# iostm32f105xx register map
Registers are 32-bit, access not given, no defined reset value unless marked. A register's access mark holds for its fields unless they carry their own. Addresses are absolute; registers are grouped by the start of their names; [hi:lo] are bit positions; {n}, {i} and the like mark numbered series.

## OTG
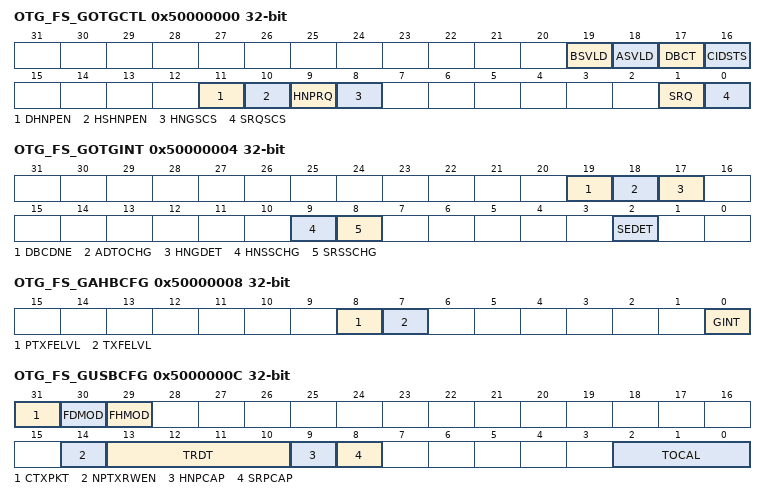
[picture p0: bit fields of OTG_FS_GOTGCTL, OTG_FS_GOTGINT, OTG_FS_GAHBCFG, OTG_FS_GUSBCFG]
0x50000000 OTG_FS_GOTGCTL
  [19] BSVLD, [18] ASVLD, [17] DBCT, [16] CIDSTS, [11] DHNPEN, [10] HSHNPEN, [9] HNPRQ, [8] HNGSCS, [1] SRQ, [0] SRQSCS
0x50000004 OTG_FS_GOTGINT
  [19] DBCDNE, [18] ADTOCHG, [17] HNGDET, [9] HNSSCHG, [8] SRSSCHG, [2] SEDET
0x50000008 OTG_FS_GAHBCFG
  [8] PTXFELVL, [7] TXFELVL, [0] GINT
0x5000000C OTG_FS_GUSBCFG
  [31] CTXPKT, [30] FDMOD, [29] FHMOD, [14] NPTXRWEN, [13:10] TRDT, [9] HNPCAP, [8] SRPCAP, [2:0] TOCAL
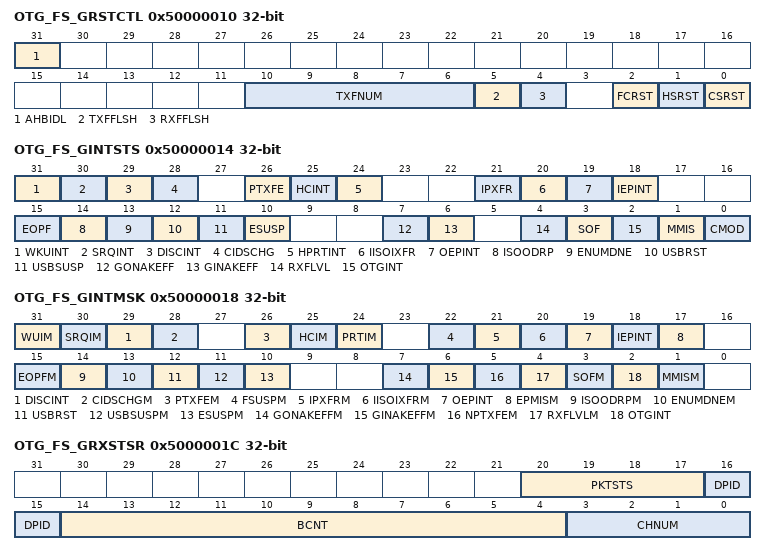
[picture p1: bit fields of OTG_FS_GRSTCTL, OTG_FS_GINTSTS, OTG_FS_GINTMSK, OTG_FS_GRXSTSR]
0x50000010 OTG_FS_GRSTCTL
  [31] AHBIDL, [10:6] TXFNUM, [5] TXFFLSH, [4] RXFFLSH, [2] FCRST, [1] HSRST, [0] CSRST
0x50000014 OTG_FS_GINTSTS
  [31] WKUINT, [30] SRQINT, [29] DISCINT, [28] CIDSCHG, [26] PTXFE, [25] HCINT, [24] HPRTINT, [21] IPXFR, [20] IISOIXFR, [19] OEPINT, [18] IEPINT, [15] EOPF, [14] ISOODRP, [13] ENUMDNE, [12] USBRST, [11] USBSUSP, [10] ESUSP, [7] GONAKEFF, [6] GINAKEFF, [4] RXFLVL, [3] SOF, [2] OTGINT, [1] MMIS, [0] CMOD
0x50000018 OTG_FS_GINTMSK
  [31] WUIM, [30] SRQIM, [29] DISCINT, [28] CIDSCHGM, [26] PTXFEM, [25] HCIM, [24] PRTIM, [22] FSUSPM, [21] IPXFRM, [20] IISOIXFRM, [19] OEPINT, [18] IEPINT, [17] EPMISM, [15] EOPFM, [14] ISOODRPM, [13] ENUMDNEM, [12] USBRST, [11] USBSUSPM, [10] ESUSPM, [7] GONAKEFFM, [6] GINAKEFFM, [5] NPTXFEM, [4] RXFLVLM, [3] SOFM, [2] OTGINT, [1] MMISM
0x5000001C OTG_FS_GRXSTSR
  [20:17] PKTSTS, [16:15] DPID, [14:4] BCNT, [3:0] CHNUM
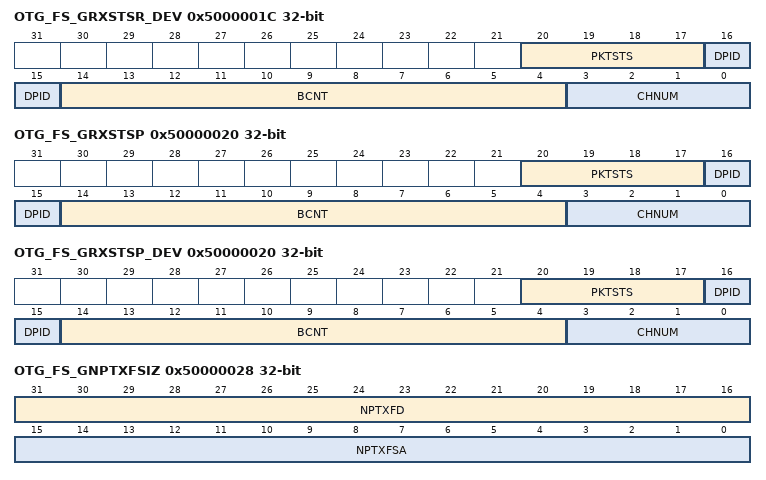
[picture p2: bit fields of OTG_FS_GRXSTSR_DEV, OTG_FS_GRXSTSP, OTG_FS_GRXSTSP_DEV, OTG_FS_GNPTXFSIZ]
0x5000001C OTG_FS_GRXSTSR_DEV
  [20:17] PKTSTS, [16:15] DPID, [14:4] BCNT, [3:0] CHNUM
0x50000020 OTG_FS_GRXSTSP
  [20:17] PKTSTS, [16:15] DPID, [14:4] BCNT, [3:0] CHNUM
0x50000020 OTG_FS_GRXSTSP_DEV
  [20:17] PKTSTS, [16:15] DPID, [14:4] BCNT, [3:0] CHNUM
0x50000024 OTG_FS_GRXFSIZ
  [15:0] RXFD
0x50000028 OTG_FS_GNPTXFSIZ
  [31:16] NPTXFD, [15:0] NPTXFSA
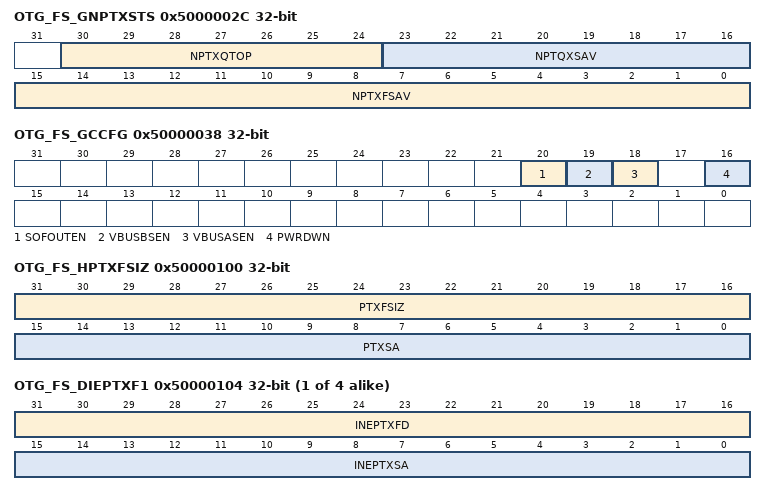
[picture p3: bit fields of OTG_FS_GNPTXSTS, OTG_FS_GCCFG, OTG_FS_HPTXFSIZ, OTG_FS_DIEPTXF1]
0x5000002C OTG_FS_GNPTXSTS
  [30:24] NPTXQTOP, [23:16] NPTQXSAV, [15:0] NPTXFSAV
0x50000038 OTG_FS_GCCFG
  [20] SOFOUTEN, [19] VBUSBSEN, [18] VBUSASEN, [16] PWRDWN
0x5000003C OTG_FS_CID
0x50000100 OTG_FS_HPTXFSIZ
  [31:16] PTXFSIZ, [15:0] PTXSA
{0x50000100+4i} OTG_FS_DIEPTXF{i} (i=1..4)
  [31:16] INEPTXFD, [15:0] INEPTXSA
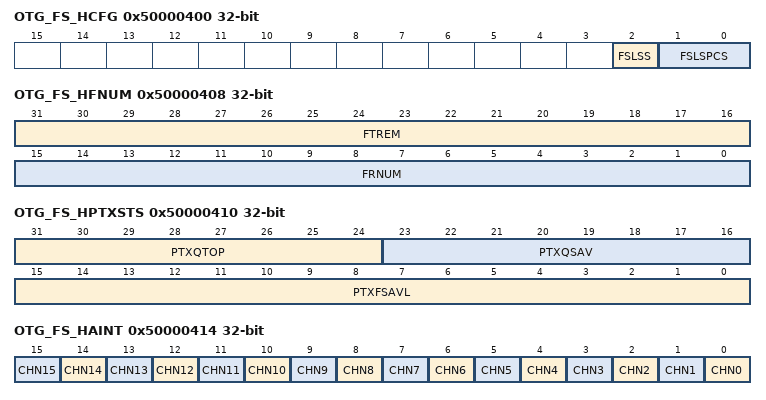
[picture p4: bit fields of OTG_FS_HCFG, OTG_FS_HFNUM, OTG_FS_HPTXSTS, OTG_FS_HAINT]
0x50000400 OTG_FS_HCFG
  [2] FSLSS, [1:0] FSLSPCS
0x50000404 OTG_FS_HFIR
  [15:0] FRIVL
0x50000408 OTG_FS_HFNUM
  [31:16] FTREM, [15:0] FRNUM
0x50000410 OTG_FS_HPTXSTS
  [31:24] PTXQTOP, [23:16] PTXQSAV, [15:0] PTXFSAVL
0x50000414 OTG_FS_HAINT
  [n] CHN{n} (n=0..15)
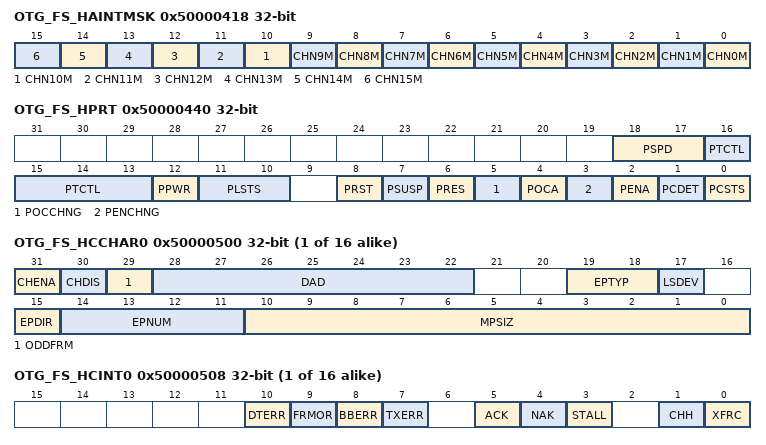
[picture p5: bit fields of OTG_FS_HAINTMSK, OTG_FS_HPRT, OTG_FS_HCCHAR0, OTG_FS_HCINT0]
0x50000418 OTG_FS_HAINTMSK
  [n] CHN{n}M (n=0..15)
0x50000440 OTG_FS_HPRT
  [18:17] PSPD, [16:13] PTCTL, [12] PPWR, [11:10] PLSTS, [8] PRST, [7] PSUSP, [6] PRES, [5] POCCHNG, [4] POCA, [3] PENCHNG, [2] PENA, [1] PCDET, [0] PCSTS
{0x50000500+0x20*i} OTG_FS_HCCHAR{i} (i=0..15)
  [31] CHENA, [30] CHDIS, [29] ODDFRM, [28:22] DAD, [19:18] EPTYP, [17] LSDEV, [15] EPDIR, [14:11] EPNUM, [10:0] MPSIZ
{0x50000508+0x20*i} OTG_FS_HCINT{i} (i=0..15)
  [10] DTERR, [9] FRMOR, [8] BBERR, [7] TXERR, [5] ACK, [4] NAK, [3] STALL, [1] CHH, [0] XFRC
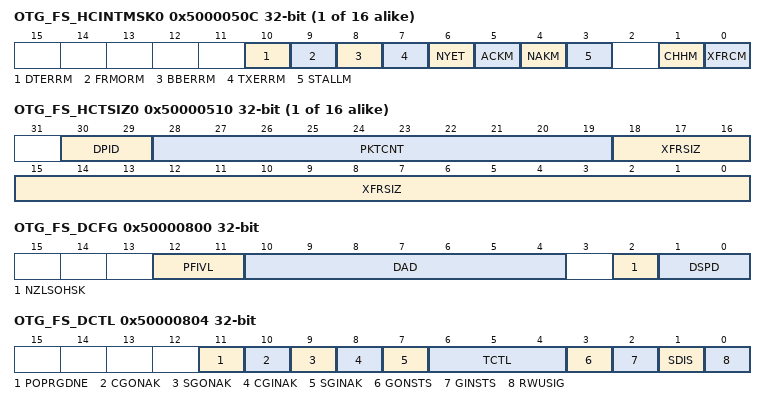
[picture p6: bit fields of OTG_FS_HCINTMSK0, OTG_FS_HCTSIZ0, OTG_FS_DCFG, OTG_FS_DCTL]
{0x5000050C+0x20*i} OTG_FS_HCINTMSK{i} (i=0..15)
  [10] DTERRM, [9] FRMORM, [8] BBERRM, [7] TXERRM, [6] NYET, [5] ACKM, [4] NAKM, [3] STALLM, [1] CHHM, [0] XFRCM
{0x50000510+0x20*i} OTG_FS_HCTSIZ{i} (i=0..15)
  [30:29] DPID, [28:19] PKTCNT, [18:0] XFRSIZ
0x50000800 OTG_FS_DCFG
  [12:11] PFIVL, [10:4] DAD, [2] NZLSOHSK, [1:0] DSPD
0x50000804 OTG_FS_DCTL
  [11] POPRGDNE, [10] CGONAK, [9] SGONAK, [8] CGINAK, [7] SGINAK, [6:4] TCTL, [3] GONSTS, [2] GINSTS, [1] SDIS, [0] RWUSIG
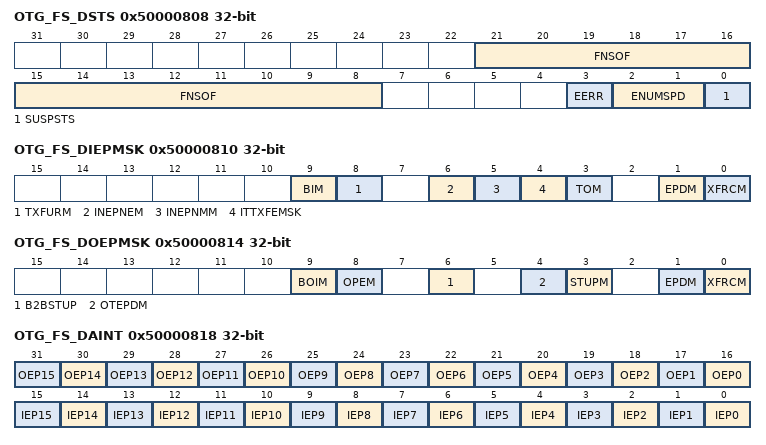
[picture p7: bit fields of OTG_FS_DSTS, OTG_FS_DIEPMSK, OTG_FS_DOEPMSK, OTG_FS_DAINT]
0x50000808 OTG_FS_DSTS
  [21:8] FNSOF, [3] EERR, [2:1] ENUMSPD, [0] SUSPSTS
0x50000810 OTG_FS_DIEPMSK
  [9] BIM, [8] TXFURM, [6] INEPNEM, [5] INEPNMM, [4] ITTXFEMSK, [3] TOM, [1] EPDM, [0] XFRCM
0x50000814 OTG_FS_DOEPMSK
  [9] BOIM, [8] OPEM, [6] B2BSTUP, [4] OTEPDM, [3] STUPM, [1] EPDM, [0] XFRCM
0x50000818 OTG_FS_DAINT
  [n+16] OEP{n} (n=0..15), [n] IEP{n} (n=0..15)
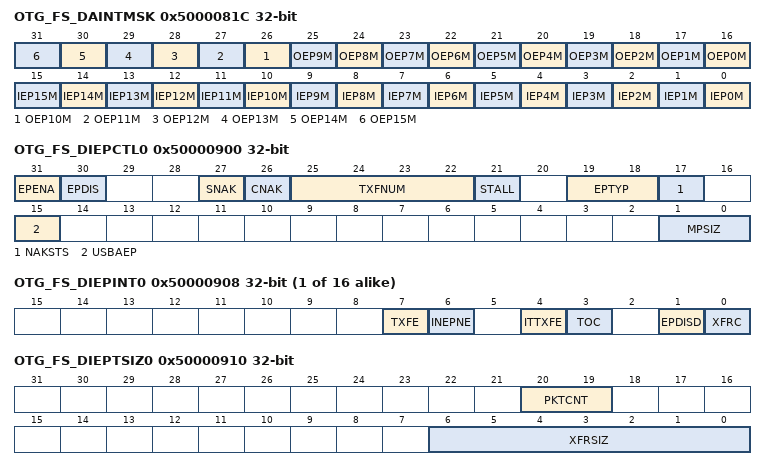
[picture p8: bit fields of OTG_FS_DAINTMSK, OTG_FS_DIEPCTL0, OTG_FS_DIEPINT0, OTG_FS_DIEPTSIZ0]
0x5000081C OTG_FS_DAINTMSK
  [n+16] OEP{n}M (n=0..15), [n] IEP{n}M (n=0..15)
0x50000828 OTG_FS_DVBUSDIS
  [15:0] VBUSDT
0x5000082C OTG_FS_DVBUSPULSE
  [11:0] DVBUSP
0x50000834 OTG_FS_DIEPEMPMSK
  [15:0] INEPTXFEM
0x50000900 OTG_FS_DIEPCTL0
  [31] EPENA, [30] EPDIS, [27] SNAK, [26] CNAK, [25:22] TXFNUM, [21] STALL, [19:18] EPTYP, [17] NAKSTS, [15] USBAEP, [1:0] MPSIZ
{0x50000908+0x20*i} OTG_FS_DIEPINT{i} (i=0..15)
  [7] TXFE, [6] INEPNE, [4] ITTXFE, [3] TOC, [1] EPDISD, [0] XFRC
0x50000910 OTG_FS_DIEPTSIZ0
  [20:19] PKTCNT, [6:0] XFRSIZ
{0x50000918+0x20*i} OTG_FS_DTXFSTS{i} (i=0..4)
  [15:0] INEPTFSAV
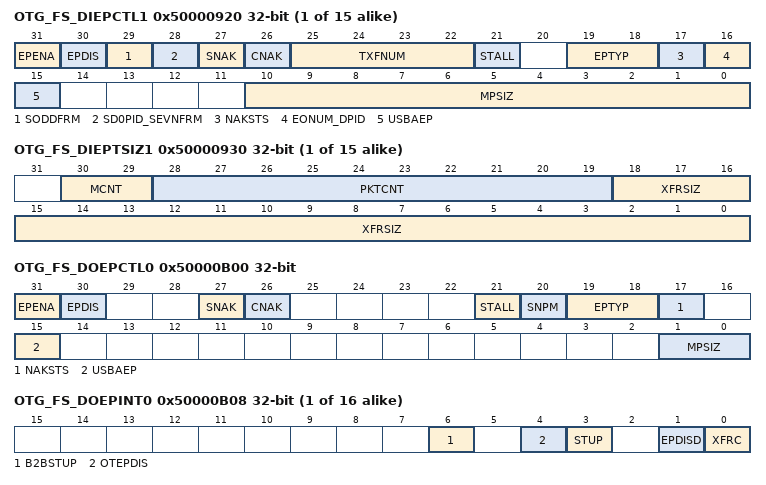
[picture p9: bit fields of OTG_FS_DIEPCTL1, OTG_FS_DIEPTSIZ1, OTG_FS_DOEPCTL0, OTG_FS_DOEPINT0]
{0x50000900+0x20*i} OTG_FS_DIEPCTL{i} (i=1..15)
  [31] EPENA, [30] EPDIS, [29] SODDFRM, [28] SD0PID_SEVNFRM, [27] SNAK, [26] CNAK, [25:22] TXFNUM, [21] STALL, [19:18] EPTYP, [17] NAKSTS, [16] EONUM_DPID, [15] USBAEP, [10:0] MPSIZ
{0x50000910+0x20*i} OTG_FS_DIEPTSIZ{i} (i=1..15)
  [30:29] MCNT, [28:19] PKTCNT, [18:0] XFRSIZ
0x50000B00 OTG_FS_DOEPCTL0
  [31] EPENA, [30] EPDIS, [27] SNAK, [26] CNAK, [21] STALL, [20] SNPM, [19:18] EPTYP, [17] NAKSTS, [15] USBAEP, [1:0] MPSIZ
{0x50000B08+0x20*i} OTG_FS_DOEPINT{i} (i=0..15)
  [6] B2BSTUP, [4] OTEPDIS, [3] STUP, [1] EPDISD, [0] XFRC
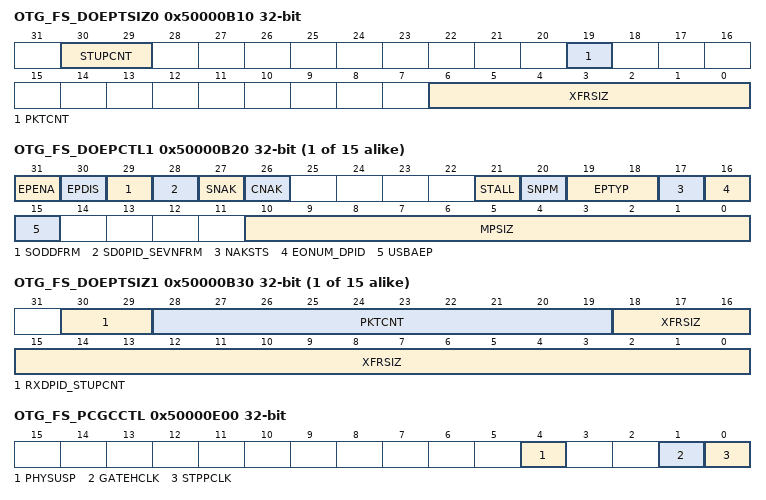
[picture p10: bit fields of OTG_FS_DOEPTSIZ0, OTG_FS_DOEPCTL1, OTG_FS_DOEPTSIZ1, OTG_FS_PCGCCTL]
0x50000B10 OTG_FS_DOEPTSIZ0
  [30:29] STUPCNT, [19] PKTCNT, [6:0] XFRSIZ
{0x50000B00+0x20*i} OTG_FS_DOEPCTL{i} (i=1..15)
  [31] EPENA, [30] EPDIS, [29] SODDFRM, [28] SD0PID_SEVNFRM, [27] SNAK, [26] CNAK, [21] STALL, [20] SNPM, [19:18] EPTYP, [17] NAKSTS, [16] EONUM_DPID, [15] USBAEP, [10:0] MPSIZ
{0x50000B10+0x20*i} OTG_FS_DOEPTSIZ{i} (i=1..15)
  [30:29] RXDPID_STUPCNT, [28:19] PKTCNT, [18:0] XFRSIZ
0x50000E00 OTG_FS_PCGCCTL
  [4] PHYSUSP, [1] GATEHCLK, [0] STPPCLK
